VERSION ""

NS_ :

BS_:

BU_:

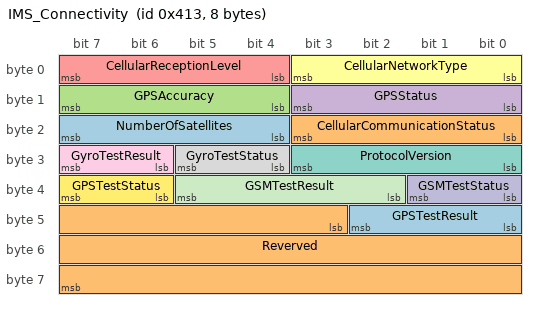
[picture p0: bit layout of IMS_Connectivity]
BO_ 1043 IMS_Connectivity: 8 Vector__XXX
 SG_ NumberOfSatellites : 20|4@1+ (1,0) [0|15] "" Vector__XXX
 SG_ CellularCommunicationStatus : 16|4@1+ (1,0) [0|15] "" Vector__XXX
 SG_ GPSAccuracy : 12|4@1+ (1,0) [0|15] "" Vector__XXX
 SG_ GPSStatus : 8|4@1+ (1,0) [0|15] "" Vector__XXX
 SG_ CellularReceptionLevel : 4|4@1+ (1,0) [0|15] "" Vector__XXX
 SG_ CellularNetworkType : 0|4@1+ (1,0) [0|15] "" Vector__XXX
 SG_ ProtocolVersion : 24|4@1+ (1,0) [0|0] "" Vector__XXX
 SG_ GyroTestStatus : 28|2@1+ (1,0) [0|0] "" Vector__XXX
 SG_ GyroTestResult : 30|2@1+ (1,0) [0|0] "" Vector__XXX
 SG_ GSMTestStatus : 32|2@1+ (1,0) [0|0] "" Vector__XXX
 SG_ GSMTestResult : 34|4@1+ (1,0) [0|0] "" Vector__XXX
 SG_ GPSTestStatus : 38|2@1+ (1,0) [0|0] "" Vector__XXX
 SG_ GPSTestResult : 40|3@1+ (1,0) [0|0] "" Vector__XXX
 SG_ Reverved : 43|21@1+ (1,0) [0|0] "" Vector__XXX

BA_DEF_  "BusType" STRING ;
BA_DEF_DEF_  "BusType" "CAN";
VAL_ 1043 CellularCommunicationStatus 0 "INVALID_UNIT_CONFIG" 1 "GSM_DISABLED" 2 "GSM_MODULE_DISCONNECTED" 3 "NO_SIM_CARD" 4 "OTHER_CRITICAL_ERROR" 5 "SEARCHING_NETWORK" 6 "REGISTER" 7 "IP_ADDRESS_ACQUIRED" 8 "SERVER_AVAILABLE" 9 "DATA_USAGE" 10 "INVALID_APN" 15 "INVALID_VALUE" ;
VAL_ 1043 GPSAccuracy 0 "0-2_METERS" 1 "2-10_METERS" 2 "10-50_METERS" 3 "50_AND_MORE_METERS" 4 "INVALID_VALUE" ;
VAL_ 1043 GPSStatus 0 "GPS_MODULE_DISCONNECTED" 1 "NO_SATELLITE" 2 "SOME_SATELLITE" 3 "LOCALIZATION" 4 "GPS_OK" 15 "INVALID_VALUE" ;
VAL_ 1043 GyroTestStatus 0 "TEST_PASS" 1 "TEST_FAILED" 2 "TEST_IN_PROGRESS" 3 "NOT_IN_TEST" ;
VAL_ 1043 GyroTestResult 0 "TEST_PASS" 1 "NO_GYRO_MESSAGES" 2 "GYRO_OUT_OF_RANGE" 3 "INVALID_VALUE" ;
VAL_ 1043 GSMTestStatus 0 "TEST_PASS" 1 "TEST_FAILED" 2 "TEST_IN_PROGRESS" 3 "NOT_IN_TEST" ;
VAL_ 1043 GSMTestResult 0 "TEST_PASS" 1 "GSM_DISABLED" 2 "MISSING_SECURITY_ARTIFACTS" 3 "GSM_MODULE_NOT_CONNECTED" 4 "APN_NOT_CONFIGURED" 5 "SIM_MISSING" 6 "SIM_APN_MISMATCH" 7 "REGISTRATION_FAILED" 8 "NO_IP" 9 "SERVER_CONNECTION_FAILED" 15 "INVALID_VALUES" ;
VAL_ 1043 GPSTestStatus 0 "TEST_PASS" 1 "TEST_FAILED" 2 "TEST_IN_PROGRESS" 3 "NOT_IN_TEST" ;
VAL_ 1043 GPSTestResult 0 "TEST_PASS" 1 "NO_GPS_MESSAGES" 2 "NO_1PPS_PULSE" 3 "GPS_NOT_LOCKED" 4 "1PPS_NOT_LOCKED" 7 "INVALID_VALUE" ;
